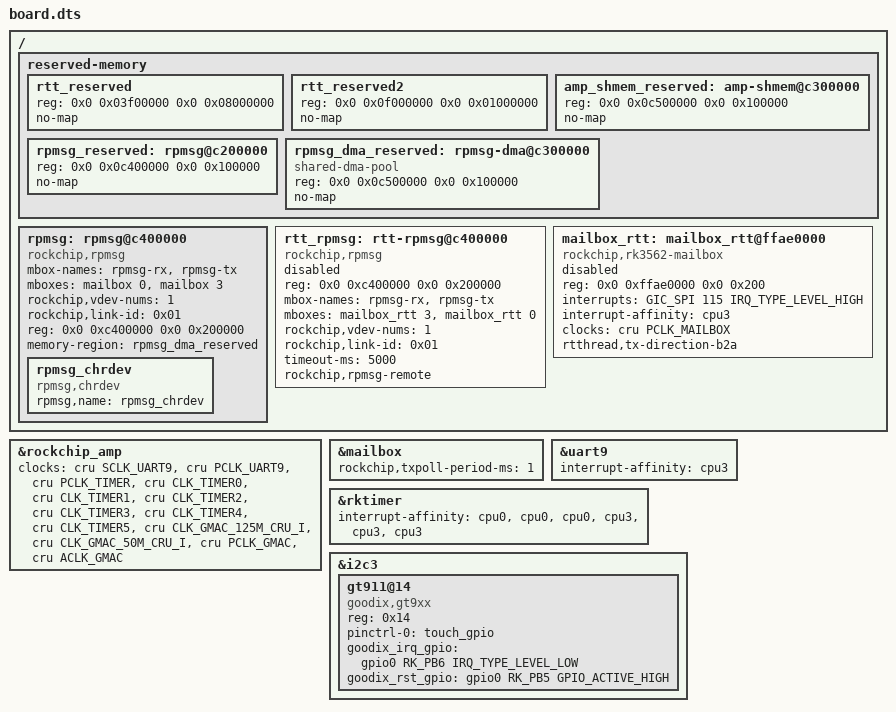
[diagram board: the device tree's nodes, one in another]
/**
 * RT-Thread RuiChing
 *
 * COPYRIGHT (C) 2024-2025 Shanghai Real-Thread Electronic Technology Co., Ltd.
 * All rights reserved.
 *
 * The license and distribution terms for this file may be
 * found in the file LICENSE in this distribution.
 */
/dts-v1/;
#include "rc-pi-3562-v1_0.dtsi"
#include "amp_shm.dtsi"

&rockchip_amp {
    clocks = <&cru SCLK_UART9>, <&cru PCLK_UART9>,
            <&cru PCLK_TIMER>, <&cru CLK_TIMER0>, <&cru CLK_TIMER1>, <&cru CLK_TIMER2>,
            <&cru CLK_TIMER3>, <&cru CLK_TIMER4>, <&cru CLK_TIMER5>,
            <&cru CLK_GMAC_125M_CRU_I>, <&cru CLK_GMAC_50M_CRU_I>,
            <&cru PCLK_GMAC>, <&cru ACLK_GMAC>;
    status = "okay";
};

/ {
	reserved-memory {
		#address-cells = <2>;
		#size-cells = <2>;
		ranges;

		/* remote amp core address */
		rtt_reserved {
			reg = <0x0 0x03f00000 0x0 0x08000000>;
			no-map;
		};

        rtt_reserved2 {
			reg = <0x0 0x0f000000 0x0 0x01000000>;
			no-map;
		};

		/* remote amp core address */
		amp_shmem_reserved: amp-shmem@c300000 {
			reg = <0x0 0x0c500000 0x0 0x100000>;
			no-map;
		};
		rpmsg_reserved: rpmsg@c200000 {
			reg = <0x0 0x0c400000 0x0 0x100000>;
			no-map;
		};
		rpmsg_dma_reserved: rpmsg-dma@c300000 {
			compatible = "shared-dma-pool";
			reg = <0x0 0x0c500000 0x0 0x100000>;
			no-map;
		};

	};

	/* 目前 rpmsg 大小需要2MB对齐 */

	rpmsg: rpmsg@c400000 {
		compatible = "rockchip,rpmsg";
		mbox-names = "rpmsg-rx", "rpmsg-tx";
		mboxes = <&mailbox 0 &mailbox 3>;
		rockchip,vdev-nums = <1>;
		rockchip,link-id = <0x01>;
		reg = <0x0 0xc400000 0x0 0x200000>;
		memory-region = <&rpmsg_dma_reserved>;
		status = "okay";

        // 方法1：使用 rpmsg_chrdev 作为服务名
        rpmsg_chrdev {
            compatible = "rpmsg,chrdev";  // 兼容性字符串
            rpmsg,name = "rpmsg_chrdev";  // 服务名
            status = "okay";
        };
	};

	rtt_rpmsg: rtt-rpmsg@c400000 {
		compatible = "rockchip,rpmsg";
		reg = <0x0 0xc400000 0x0 0x200000>;
		mbox-names = "rpmsg-rx", "rpmsg-tx";
		mboxes = <&mailbox_rtt 3 &mailbox_rtt 0>;
		rockchip,vdev-nums = <1>;
		rockchip,link-id = <0x01>;
		timeout-ms = <5000>;
		status = "okay,rtt";
		rockchip,rpmsg-remote;
    };

	mailbox_rtt: mailbox_rtt@ffae0000 {
		compatible = "rockchip,rk3562-mailbox",
			     "rockchip,rk3368-mailbox";
		reg = <0x0 0xffae0000 0x0 0x200>;
		interrupts = <GIC_SPI 115 IRQ_TYPE_LEVEL_HIGH>;
	    interrupt-affinity = <&cpu3>;
		clocks = <&cru PCLK_MAILBOX>;
		clock-names = "pclk_mailbox";
		#mbox-cells = <1>;
		rtthread,tx-direction-b2a;
		status = "okay,rtt";
	};

};

&mailbox {
	rockchip,txpoll-period-ms = <1>;
	status = "okay";
};

&uart9 {
	pinctrl-names = "default";
	interrupt-affinity = <&cpu3>;
};

&rktimer {
    interrupt-affinity = <&cpu0>, <&cpu0>, <&cpu0>, <&cpu3>, <&cpu3>, <&cpu3>;
};

&i2c3 {
	status = "okay";
	gt911@14 {
		compatible = "goodix,gt9xx";
		reg = <0x14>;
		pinctrl-names = "default";
		pinctrl-0 = <&touch_gpio>;
		goodix_irq_gpio = <&gpio0 RK_PB6 IRQ_TYPE_LEVEL_LOW>;
		goodix_rst_gpio = <&gpio0 RK_PB5 GPIO_ACTIVE_HIGH>;
		status = "okay";
	};
};
